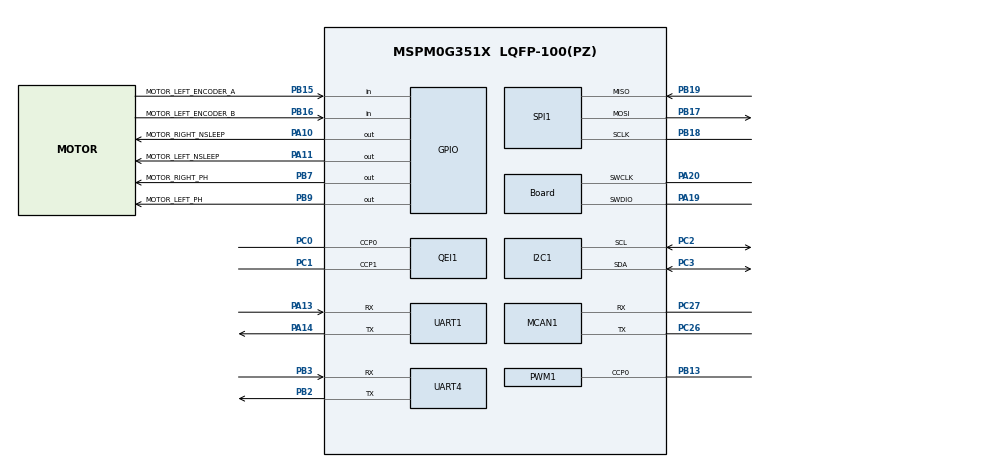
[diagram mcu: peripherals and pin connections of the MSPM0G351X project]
/**
 * @cliArgs --device "MSPM0G351X" --part "Default" --package "LQFP-100(PZ)" --product "mspm0_sdk@2.10.00.04"
 * @versions {"tool":"1.26.2+4477"}
 */

/**
 * Import the modules used in this configuration.
 */
const ADC12  = scripting.addModule("/ti/driverlib/ADC12", {}, false);
const ADC121 = ADC12.addInstance();
const GPIO   = scripting.addModule("/ti/driverlib/GPIO", {}, false);
const GPIO1  = GPIO.addInstance();
const GPIO2  = GPIO.addInstance();
const GPIO3  = GPIO.addInstance();
const GPIO4  = GPIO.addInstance();
const GPIO5  = GPIO.addInstance();
const GPIO6  = GPIO.addInstance();
const GPIO7  = GPIO.addInstance();
const GPIO8  = GPIO.addInstance();
const GPIO9  = GPIO.addInstance();
const GPIO10 = GPIO.addInstance();
const GPIO11 = GPIO.addInstance();
const GPIO12 = GPIO.addInstance();
const GPIO13 = GPIO.addInstance();
const I2C    = scripting.addModule("/ti/driverlib/I2C", {}, false);
const I2C1   = I2C.addInstance();
const MCAN   = scripting.addModule("/ti/driverlib/MCAN", {}, false);
const MCAN1  = MCAN.addInstance();
const PWM    = scripting.addModule("/ti/driverlib/PWM", {}, false);
const PWM1   = PWM.addInstance();
const QEI    = scripting.addModule("/ti/driverlib/QEI", {}, false);
const QEI1   = QEI.addInstance();
const SPI    = scripting.addModule("/ti/driverlib/SPI", {}, false);
const SPI1   = SPI.addInstance();
const SYSCTL = scripting.addModule("/ti/driverlib/SYSCTL");
const UART   = scripting.addModule("/ti/driverlib/UART", {}, false);
const UART1  = UART.addInstance();
const UART4  = UART.addInstance();

/**
 * Write custom configuration values to the imported modules.
 */
const divider6       = system.clockTree["PLL_CLK2X_DIV"];
divider6.divideValue = 4;

const divider7       = system.clockTree["PLL_PDIV"];
divider7.divideValue = 2;

const divider9       = system.clockTree["UDIV"];
divider9.divideValue = 2;

const multiplier2         = system.clockTree["PLL_QDIV"];
multiplier2.multiplyValue = 10;

const mux8       = system.clockTree["HSCLKMUX"];
mux8.inputSelect = "HSCLKMUX_SYSPLL2X";

/* CANFD1 uses the 80 MHz SYSPLLCLK1 output without changing MCLK/HSCLK. */
const canPllClk1Div = system.clockTree["PLL_CLK1_DIV"];
canPllClk1Div.divideValue = 2;

const canClockMux = system.clockTree["CANCLKMUX"];
canClockMux.inputSelect = "CANCLKMUX_PLLCLK1_OUT";

ADC121.$name                             = "GRAYSCALE_ADC";
ADC121.sampClkSrc                        = "DL_ADC12_CLOCK_ULPCLK";
ADC121.sampClkDiv                        = "DL_ADC12_CLOCK_DIVIDE_8";
ADC121.sampleTime0                       = "125 us";
ADC121.adcMem0avgen                      = true;
ADC121.hwNumerator                       = "DL_ADC12_HW_AVG_NUM_ACC_4";
ADC121.hwDenominator                     = "DL_ADC12_HW_AVG_DEN_DIV_BY_4";
ADC121.enabledInterrupts                 = ["DL_ADC12_INTERRUPT_MEM0_RESULT_LOADED"];
ADC121.interruptPriority                 = "3";
ADC121.powerDownMode                     = "DL_ADC12_POWER_DOWN_MODE_MANUAL";
ADC121.sampCnt                           = 1;
ADC121.peripheral.$assign                = "ADC1";
ADC121.peripheral.adcPin0.$assign        = "PA15";
ADC121.adcPin0Config.hideOutputInversion = scripting.forceWrite(false);
ADC121.adcPin0Config.$name               = "ti_driverlib_gpio_GPIOPinGeneric14";

const Board                       = scripting.addModule("/ti/driverlib/Board", {}, false);
Board.peripheral.$assign          = "DEBUGSS";
Board.peripheral.swclkPin.$assign = "PA20";
Board.peripheral.swdioPin.$assign = "PA19";

GPIO1.$name                          = "GPIO_LED_A";
GPIO1.port                           = "PORTA";
GPIO1.portSegment                    = "Upper";
GPIO1.associatedPins.create(2);
GPIO1.associatedPins[0].$name        = "LED1";
GPIO1.associatedPins[0].initialValue = "SET";
GPIO1.associatedPins[0].assignedPin  = "27";
GPIO1.associatedPins[1].$name        = "LED2";
GPIO1.associatedPins[1].initialValue = "SET";
GPIO1.associatedPins[1].assignedPin  = "26";

GPIO2.$name                         = "GPIO_BUZZER";
GPIO2.port                          = "PORTC";
GPIO2.portSegment                   = "Upper";
GPIO2.associatedPins[0].$name       = "BUZZER";
GPIO2.associatedPins[0].assignedPin = "16";

GPIO3.$name                              = "GPIO_BUTTON_C";
GPIO3.port                               = "PORTC";
GPIO3.portSegment                        = "Lower";
GPIO3.associatedPins[0].$name            = "BUTTON1";
GPIO3.associatedPins[0].direction        = "INPUT";
GPIO3.associatedPins[0].internalResistor = "PULL_UP";
GPIO3.associatedPins[0].assignedPin      = "9";

GPIO4.$name                              = "GPIO_BUTTON_B";
GPIO4.port                               = "PORTB";
GPIO4.portSegment                        = "Upper";
GPIO4.associatedPins.create(2);
GPIO4.associatedPins[0].$name            = "BUTTON2";
GPIO4.associatedPins[0].direction        = "INPUT";
GPIO4.associatedPins[0].internalResistor = "PULL_UP";
GPIO4.associatedPins[0].assignedPin      = "20";
GPIO4.associatedPins[1].$name            = "BUTTON3";
GPIO4.associatedPins[1].direction        = "INPUT";
GPIO4.associatedPins[1].internalResistor = "PULL_UP";
GPIO4.associatedPins[1].assignedPin      = "23";

GPIO5.$name                          = "GPIO_IMU_C";
GPIO5.port                           = "PORTC";
GPIO5.portSegment                    = "Lower";
GPIO5.associatedPins.create(3);
GPIO5.associatedPins[0].$name        = "ICM45686_INT1";
GPIO5.associatedPins[0].direction    = "INPUT";
GPIO5.associatedPins[0].assignedPin  = "6";
GPIO5.associatedPins[1].$name        = "ICM45686_CS";
GPIO5.associatedPins[1].initialValue = "SET";
GPIO5.associatedPins[1].assignedPin  = "7";
GPIO5.associatedPins[2].$name        = "LIS3MDL_CS";
GPIO5.associatedPins[2].initialValue = "SET";
GPIO5.associatedPins[2].assignedPin  = "8";

GPIO6.$name                         = "GPIO_IMU_A";
GPIO6.port                          = "PORTA";
GPIO6.portSegment                   = "Upper";
GPIO6.associatedPins.create(2);
GPIO6.associatedPins[0].$name       = "LIS3MDL_DRDY";
GPIO6.associatedPins[0].direction   = "INPUT";
GPIO6.associatedPins[0].assignedPin = "22";
GPIO6.associatedPins[1].$name       = "ICM45686_INT2_FSYNC";
GPIO6.associatedPins[1].direction   = "INPUT";
GPIO6.associatedPins[1].assignedPin = "31";

GPIO7.$name                          = "GPIO_LED_B";
GPIO7.port                           = "PORTB";
GPIO7.portSegment                    = "Upper";
GPIO7.associatedPins[0].$name        = "LED3";
GPIO7.associatedPins[0].initialValue = "SET";
GPIO7.associatedPins[0].assignedPin  = "27";

GPIO8.$name                              = "GPIO_GY931_I2C";
GPIO8.port                               = "PORTA";
GPIO8.portSegment                        = "Upper";
GPIO8.associatedPins.create(2);
GPIO8.associatedPins[0].$name            = "GY931_SCL";
GPIO8.associatedPins[0].direction        = "INPUT";
GPIO8.associatedPins[0].internalResistor = "PULL_UP";
GPIO8.associatedPins[0].assignedPin      = "29";
GPIO8.associatedPins[1].$name            = "GY931_SDA";
GPIO8.associatedPins[1].direction        = "INPUT";
GPIO8.associatedPins[1].internalResistor = "PULL_UP";
GPIO8.associatedPins[1].assignedPin      = "30";

GPIO9.$name                         = "GPIO_GRAY_C";
GPIO9.port                          = "PORTC";
GPIO9.portSegment                   = "Upper";
GPIO9.associatedPins.create(2);
GPIO9.associatedPins[0].$name       = "GRAY_SEL0";
GPIO9.associatedPins[0].assignedPin = "21";
GPIO9.associatedPins[1].$name       = "GRAY_SEL1";
GPIO9.associatedPins[1].assignedPin = "20";

GPIO10.$name                         = "GPIO_GRAY_A";
GPIO10.port                          = "PORTA";
GPIO10.portSegment                   = "Upper";
GPIO10.associatedPins[0].$name       = "GRAY_SEL2";
GPIO10.associatedPins[0].assignedPin = "16";

/* TCAN3413 STB: low=Normal, high=Standby. */
GPIO11.$name                                      = "GPIO_CAN_CTRL";
GPIO11.port                                       = "PORTC";
GPIO11.portSegment                                = "Upper";
GPIO11.associatedPins[0].$name                    = "CAN_STB";
GPIO11.associatedPins[0].initialValue             = "CLEARED";
GPIO11.associatedPins[0].assignedPin              = "25";

/* Keep both DRV8876 bridges asleep until board initialization completes. */
GPIO12.$name                                  = "GPIO_MOTOR_SLEEP";
GPIO12.port                                   = "PORTA";
GPIO12.portSegment                            = "Lower";
GPIO12.associatedPins.create(2);
GPIO12.associatedPins[0].$name                = "MOTOR_RIGHT_NSLEEP";
GPIO12.associatedPins[0].initialValue         = "CLEARED";
GPIO12.associatedPins[0].assignedPin          = "10";
GPIO12.associatedPins[0].pin.$assign          = "PA10";
GPIO12.associatedPins[1].$name                = "MOTOR_LEFT_NSLEEP";
GPIO12.associatedPins[1].initialValue         = "CLEARED";
GPIO12.associatedPins[1].assignedPin          = "11";
GPIO12.associatedPins[1].pin.$assign          = "PA11";

GPIO13.$name                                  = "GPIO_MOTOR_DIRECTION";
GPIO13.port                                   = "PORTB";
GPIO13.portSegment                            = "Any";
GPIO13.associatedPins.create(4);
GPIO13.associatedPins[0].$name                = "MOTOR_RIGHT_PH";
GPIO13.associatedPins[0].initialValue         = "CLEARED";
GPIO13.associatedPins[0].assignedPin          = "7";
GPIO13.associatedPins[0].pin.$assign          = "PB7";
GPIO13.associatedPins[1].$name                = "MOTOR_LEFT_PH";
GPIO13.associatedPins[1].initialValue         = "CLEARED";
GPIO13.associatedPins[1].assignedPin          = "9";
GPIO13.associatedPins[1].pin.$assign          = "PB9";
/* The unused left encoder remains input-only; never drive its outputs. */
GPIO13.associatedPins[2].$name                = "MOTOR_LEFT_ENCODER_A";
GPIO13.associatedPins[2].direction            = "INPUT";
GPIO13.associatedPins[2].assignedPin          = "15";
GPIO13.associatedPins[2].pin.$assign          = "PB15";
GPIO13.associatedPins[3].$name                = "MOTOR_LEFT_ENCODER_B";
GPIO13.associatedPins[3].direction            = "INPUT";
GPIO13.associatedPins[3].assignedPin          = "16";
GPIO13.associatedPins[3].pin.$assign          = "PB16";

I2C1.basicEnableController             = true;
I2C1.basicControllerBusSpeed           = 400000;
I2C1.$name                             = "SENSOR_I2C";
I2C1.advAnalogGlitchFilter             = "DISABLED";
I2C1.peripheral.$assign                = "I2C2";
I2C1.peripheral.sdaPin.$assign         = "PC3";
I2C1.peripheral.sclPin.$assign         = "PC2";
I2C1.sdaPinConfig.hideOutputInversion  = scripting.forceWrite(false);
I2C1.sdaPinConfig.onlyInternalResistor = scripting.forceWrite(false);
I2C1.sdaPinConfig.passedPeripheralType = scripting.forceWrite("Digital");
I2C1.sdaPinConfig.$name                = "ti_driverlib_gpio_GPIOPinGeneric6";
I2C1.sclPinConfig.hideOutputInversion  = scripting.forceWrite(false);
I2C1.sclPinConfig.onlyInternalResistor = scripting.forceWrite(false);
I2C1.sclPinConfig.passedPeripheralType = scripting.forceWrite("Digital");
I2C1.sclPinConfig.$name                = "ti_driverlib_gpio_GPIOPinGeneric7";

PWM1.$name                              = "MOTOR_PWM";
PWM1.ccIndex                            = [0];
PWM1.clockDivider                       = 2;
PWM1.timerCount                         = 2000;
PWM1.timerStartTimer                    = false;
PWM1.peripheral.$assign                 = "TIMG12";
PWM1.peripheral.ccp0Pin.$assign         = "PB13";
PWM1.ccp0PinConfig.$name                = "GPIO_MOTOR_RIGHT_PWM";
PWM1.PWM_CHANNEL_0.$name                = "MOTOR_RIGHT_PWM_CHANNEL";
PWM1.PWM_CHANNEL_0.initVal              = "LOW";
PWM1.PWM_CHANNEL_0.dutyCycle            = 0;

QEI1.$name                              = "RIGHT_MOTOR_QEI";
QEI1.loadValue                          = 0xFFFF;
QEI1.timerStartTimer                    = false;
QEI1.peripheral.$assign                 = "TIMG8";
QEI1.peripheral.ccp0Pin.$assign         = "PC0";
QEI1.peripheral.ccp1Pin.$assign         = "PC1";
QEI1.ccp0PinConfig.$name                = "GPIO_RIGHT_MOTOR_QEI_PHA";
QEI1.ccp0PinConfig.enableConfig         = true;
QEI1.ccp0PinConfig.internalResistor      = "PULL_UP";
QEI1.ccp1PinConfig.$name                = "GPIO_RIGHT_MOTOR_QEI_PHB";
QEI1.ccp1PinConfig.enableConfig         = true;
QEI1.ccp1PinConfig.internalResistor      = "PULL_UP";

SPI1.$name                              = "IMU_SPI";
SPI1.targetBitRate                      = 1000000;
SPI1.frameFormat                        = "MOTO3";
SPI1.polarity                           = "1";
SPI1.phase                              = "1";
SPI1.sclkPinConfig.direction            = scripting.forceWrite("OUTPUT");
SPI1.sclkPinConfig.onlyInternalResistor = scripting.forceWrite(false);
SPI1.sclkPinConfig.passedPeripheralType = scripting.forceWrite("Digital");
SPI1.sclkPinConfig.$name                = "ti_driverlib_gpio_GPIOPinGeneric10";
SPI1.mosiPinConfig.direction            = scripting.forceWrite("OUTPUT");
SPI1.mosiPinConfig.hideOutputInversion  = scripting.forceWrite(false);
SPI1.mosiPinConfig.onlyInternalResistor = scripting.forceWrite(false);
SPI1.mosiPinConfig.passedPeripheralType = scripting.forceWrite("Digital");
SPI1.mosiPinConfig.$name                = "ti_driverlib_gpio_GPIOPinGeneric11";
SPI1.misoPinConfig.onlyInternalResistor = scripting.forceWrite(false);
SPI1.misoPinConfig.passedPeripheralType = scripting.forceWrite("Digital");
SPI1.misoPinConfig.$name                = "ti_driverlib_gpio_GPIOPinGeneric12";
SPI1.peripheral.sclkPin.$assign         = "PB18";
SPI1.peripheral.mosiPin.$assign         = "PB17";
SPI1.peripheral.misoPin.$assign         = "PB19";

SYSCTL.forceDefaultClkConfig = true;
SYSCTL.clockTreeEn           = true;
SYSCTL.validateClkStatus     = true;
SYSCTL.SYSPLL_CLK1En         = true;

/*
 * TCAN3413 classic CAN debug interface. CANFD1_CANTX on PC26 drives TXD;
 * CANFD1_CANRX on PC27 receives RXD. All standard and extended data frames
 * are routed to FIFO0; remote frames are rejected.
 */
MCAN1.$name                     = "CAN_BUS";
MCAN1.fdMode                   = false;
MCAN1.brsEnable                = false;
MCAN1.desiredNomRate           = 250;
MCAN1.spPercent                = 80;
MCAN1.additionalCoreConfig     = true;
MCAN1.wkupReqEnable            = true;
MCAN1.autoWkupEnable           = true;
MCAN1.emulationEnable          = true;
MCAN1.tdcEnable                = false;
MCAN1.rrfe                     = true;
MCAN1.rrfs                     = true;
MCAN1.anfe                     = "0";
MCAN1.anfs                     = "0";
MCAN1.flssa                    = 0;
MCAN1.lss                      = 0;
MCAN1.flesa                    = 0;
MCAN1.lse                      = 0;
MCAN1.txStartAddr              = 0;
MCAN1.txBufNum                 = 1;
MCAN1.txFIFOSize               = 0;
MCAN1.txBufElemSize            = "DL_MCAN_ELEM_SIZE_8BYTES";
MCAN1.txEventFIFOStartAddr     = 4;
MCAN1.txEventFIFOSize          = 0;
MCAN1.rxFIFO0startAddr         = 16;
MCAN1.rxFIFO0size              = 16;
MCAN1.rxFIFO0waterMark         = 0;
MCAN1.rxFIFO0ElemSize          = "DL_MCAN_ELEM_SIZE_8BYTES";
MCAN1.rxFIFO1startAddr         = 0;
MCAN1.rxFIFO1size              = 0;
MCAN1.rxFIFO1waterMark         = 0;
MCAN1.rxFIFO1ElemSize          = "DL_MCAN_ELEM_SIZE_8BYTES";
MCAN1.rxBufStartAddr           = 272;
MCAN1.rxBufElemSize            = "DL_MCAN_ELEM_SIZE_8BYTES";
MCAN1.enableInterrupt          = true;
MCAN1.interruptFlags           = ["DL_MCAN_INTERRUPT_BO","DL_MCAN_INTERRUPT_EP","DL_MCAN_INTERRUPT_EW","DL_MCAN_INTERRUPT_MRAF","DL_MCAN_INTERRUPT_PEA","DL_MCAN_INTERRUPT_PED","DL_MCAN_INTERRUPT_RF0L","DL_MCAN_INTERRUPT_RF0N","DL_MCAN_INTERRUPT_TC","DL_MCAN_INTERRUPT_TCF"];
MCAN1.interruptLine            = ["DL_MCAN_INTR_LINE_NUM_1"];
MCAN1.interruptLine1Flag       = ["DL_MCAN_INTR_MASK_ALL"];
MCAN1.m0interrupts             = ["DL_MCAN_MSP_INTERRUPT_LINE1"];
MCAN1.overrideRetention        = true;
MCAN1.peripheral.$assign       = "CANFD1";
MCAN1.peripheral.txPin.$assign = "PC26";
MCAN1.peripheral.rxPin.$assign = "PC27";
MCAN1.txPinConfig.$name        = "ti_driverlib_gpio_GPIOPinGeneric16";
MCAN1.rxPinConfig.$name        = "ti_driverlib_gpio_GPIOPinGeneric17";

UART1.$name                             = "DEBUG_UART";
UART1.rxFifoThreshold                   = "DL_UART_RX_FIFO_LEVEL_ONE_ENTRY";
UART1.targetBaudRate                    = 115200;
UART1.enableFIFO                        = true;
UART1.txFifoThreshold                   = "DL_UART_TX_FIFO_LEVEL_ONE_ENTRY";
UART1.enableDMARX                       = false;
UART1.enabledDMATXTriggers              = "DL_UART_DMA_INTERRUPT_TX";
UART1.enabledInterrupts                 = ["DMA_DONE_TX","RX"];
UART1.peripheral.$assign                = "UART3";
UART1.peripheral.rxPin.$assign          = "PA13";
UART1.peripheral.txPin.$assign          = "PA14";
UART1.txPinConfig.direction             = scripting.forceWrite("OUTPUT");
UART1.txPinConfig.hideOutputInversion   = scripting.forceWrite(false);
UART1.txPinConfig.onlyInternalResistor  = scripting.forceWrite(false);
UART1.txPinConfig.passedPeripheralType  = scripting.forceWrite("Digital");
UART1.txPinConfig.$name                 = "ti_driverlib_gpio_GPIOPinGeneric0";
UART1.rxPinConfig.hideOutputInversion   = scripting.forceWrite(false);
UART1.rxPinConfig.onlyInternalResistor  = scripting.forceWrite(false);
UART1.rxPinConfig.passedPeripheralType  = scripting.forceWrite("Digital");
UART1.rxPinConfig.$name                 = "ti_driverlib_gpio_GPIOPinGeneric1";
UART1.DMA_CHANNEL_TX.$name              = "DEBUG_UART_DMA_TX";
UART1.DMA_CHANNEL_TX.addressMode        = "b2f";
UART1.DMA_CHANNEL_TX.srcLength          = "BYTE";
UART1.DMA_CHANNEL_TX.dstLength          = "BYTE";
UART1.DMA_CHANNEL_TX.peripheral.$assign = "DMA_CH0";

UART4.$name                    = "UART_0";
UART4.peripheral.rxPin.$assign = "PB3";
UART4.peripheral.txPin.$assign = "PB2";
UART4.txPinConfig.$name        = "ti_driverlib_gpio_GPIOPinGeneric13";
UART4.rxPinConfig.$name        = "ti_driverlib_gpio_GPIOPinGeneric15";

const ProjectConfig              = scripting.addModule("/ti/project_config/ProjectConfig", {}, false);
ProjectConfig.migrationCondition = true;

/**
 * Pinmux solution for unlocked pins/peripherals. This ensures that minor changes to the automatic solver in a future
 * version of the tool will not impact the pinmux you originally saw.  These lines can be completely deleted in order to
 * re-solve from scratch.
 */
GPIO1.associatedPins[0].pin.$suggestSolution  = "PA27";
GPIO1.associatedPins[1].pin.$suggestSolution  = "PA26";
GPIO2.associatedPins[0].pin.$suggestSolution  = "PC16";
GPIO3.associatedPins[0].pin.$suggestSolution  = "PC9";
GPIO4.associatedPins[0].pin.$suggestSolution  = "PB20";
GPIO4.associatedPins[1].pin.$suggestSolution  = "PB23";
GPIO5.associatedPins[0].pin.$suggestSolution  = "PC6";
GPIO5.associatedPins[1].pin.$suggestSolution  = "PC7";
GPIO5.associatedPins[2].pin.$suggestSolution  = "PC8";
GPIO6.associatedPins[0].pin.$suggestSolution  = "PA22";
GPIO6.associatedPins[1].pin.$suggestSolution  = "PA31";
GPIO7.associatedPins[0].pin.$suggestSolution  = "PB27";
GPIO8.associatedPins[0].pin.$suggestSolution  = "PA29";
GPIO8.associatedPins[1].pin.$suggestSolution  = "PA30";
GPIO9.associatedPins[0].pin.$suggestSolution  = "PC21";
GPIO9.associatedPins[1].pin.$suggestSolution  = "PC20";
GPIO10.associatedPins[0].pin.$suggestSolution = "PA16";
GPIO11.associatedPins[0].pin.$suggestSolution = "PC25";
SPI1.peripheral.$suggestSolution              = "SPI0";
UART4.peripheral.$suggestSolution             = "UART7";
